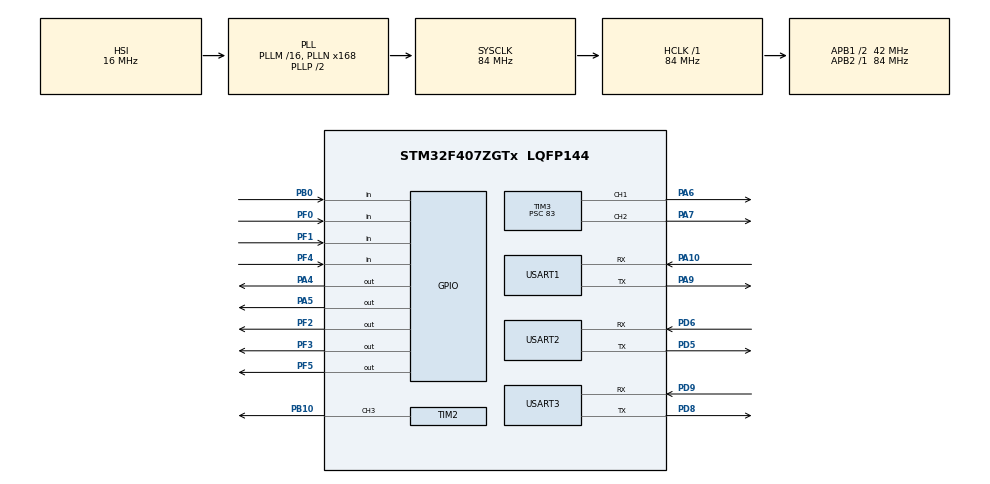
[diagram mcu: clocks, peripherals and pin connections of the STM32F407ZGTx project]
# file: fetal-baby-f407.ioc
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Mcu.Family=STM32F4
Mcu.Name=STM32F407ZGTx
Mcu.Package=LQFP144
NVIC.PriorityGroup=NVIC_PRIORITYGROUP_4
NVIC.USART1_IRQn=true\:6\:0\:false\:false\:true\:true\:true\:true
NVIC.USART2_IRQn=true\:5\:0\:false\:false\:true\:true\:true\:true
NVIC.USART3_IRQn=true\:5\:0\:false\:false\:true\:true\:true\:true
PA4.GPIO_Speed=GPIO_SPEED_FREQ_LOW
PA4.Signal=GPIO_Output
PA5.GPIO_Speed=GPIO_SPEED_FREQ_LOW
PA5.Signal=GPIO_Output
PA6.GPIO_Speed=GPIO_SPEED_FREQ_LOW
PA6.Signal=S_TIM3_CH1
PA7.GPIO_Speed=GPIO_SPEED_FREQ_LOW
PA7.Signal=S_TIM3_CH2
PA9.GPIO_Speed=GPIO_SPEED_FREQ_LOW
PA9.Mode=Asynchronous
PA9.Signal=USART1_TX
PA10.GPIO_Speed=GPIO_SPEED_FREQ_LOW
PA10.Mode=Asynchronous
PA10.Signal=USART1_RX
PA13\ (JTMS-SWDIO).Mode=Serial_Wire
PA13\ (JTMS-SWDIO).Signal=SYS_JTMS-SWDIO
PA14\ (JTCK-SWCLK).Mode=Serial_Wire
PA14\ (JTCK-SWCLK).Signal=SYS_JTCK-SWCLK
PB0.GPIO_PuPd=GPIO_PULLUP
PB0.Signal=GPIO_Input
PB10.GPIO_Speed=GPIO_SPEED_FREQ_LOW
PB10.Signal=S_TIM2_CH3
PD5.GPIO_Speed=GPIO_SPEED_FREQ_LOW
PD5.Mode=Asynchronous
PD5.Signal=USART2_TX
PD6.GPIO_Speed=GPIO_SPEED_FREQ_LOW
PD6.Mode=Asynchronous
PD6.Signal=USART2_RX
PD8.GPIO_Speed=GPIO_SPEED_FREQ_LOW
PD8.Mode=Asynchronous
PD8.Signal=USART3_TX
PD9.GPIO_Speed=GPIO_SPEED_FREQ_LOW
PD9.Mode=Asynchronous
PD9.Signal=USART3_RX
PF0.GPIO_PuPd=GPIO_PULLDOWN
PF0.Signal=GPIO_Input
PF1.GPIO_PuPd=GPIO_PULLDOWN
PF1.Signal=GPIO_Input
PF2.GPIO_Speed=GPIO_SPEED_FREQ_LOW
PF2.Signal=GPIO_Output
PF3.GPIO_Speed=GPIO_SPEED_FREQ_LOW
PF3.Signal=GPIO_Output
PF4.GPIO_PuPd=GPIO_PULLDOWN
PF4.Signal=GPIO_Input
PF5.GPIO_Speed=GPIO_SPEED_FREQ_LOW
PF5.Signal=GPIO_Output
ProjectManager.HeapSize=0x200
ProjectManager.StackSize=0x1000
ProjectManager.TargetToolchain=STM32CubeIDE
RCC.AHBFreq_Value=84000000
RCC.APB1CLKDivider=RCC_HCLK_DIV2
RCC.APB1Freq_Value=42000000
RCC.APB1TimFreq_Value=84000000
RCC.APB2Freq_Value=84000000
RCC.APB2TimFreq_Value=84000000
RCC.CortexFreq_Value=84000000
RCC.HCLKFreq_Value=84000000
RCC.HSE_VALUE=8000000
RCC.PLLM=16
RCC.PLLN=168
RCC.PLLP=RCC_PLLP_DIV2
RCC.PLLQ=7
RCC.PLLSourceVirtual=RCC_PLLSOURCE_HSI
RCC.SYSCLKFreq_VALUE=84000000
RCC.SYSCLKSource=RCC_SYSCLKSOURCE_PLLCLK
RCC.VCOOutputFreq_Value=168000000
SH.S_TIM2_CH3.0=TIM2_CH3,PWM Generation3 CH3
SH.S_TIM3_CH1.0=TIM3_CH1,PWM Generation1 CH1
SH.S_TIM3_CH2.0=TIM3_CH2,PWM Generation2 CH2
TIM2.Channel-PWM\ Generation3\ CH3=TIM_CHANNEL_3
TIM2.Period=99
TIM2.Prescaler=83
TIM3.Channel-PWM\ Generation1\ CH1=TIM_CHANNEL_1
TIM3.Channel-PWM\ Generation2\ CH2=TIM_CHANNEL_2
TIM3.Period=19999
TIM3.Prescaler=83
TIM3.Pulse-PWM\ Generation1\ CH1=1500
TIM3.Pulse-PWM\ Generation2\ CH2=1500
USART1.VirtualMode-Asynchronous=VM_ASYNC
USART2.VirtualMode-Asynchronous=VM_ASYNC
USART3.VirtualMode-Asynchronous=VM_ASYNC
VP_TIM2_VS_ClockSourceINT.Mode=Internal
VP_TIM3_VS_ClockSourceINT.Mode=Internal
board=custom

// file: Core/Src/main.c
/* USER CODE BEGIN Header */
/**
  ******************************************************************************
  * @file           : main.c
  * @brief          : Main program body
  ******************************************************************************
  * @attention
  *
  * Copyright (c) 2026 STMicroelectronics.
  * All rights reserved.
  *
  * This software is licensed under terms that can be found in the LICENSE file
  * in the root directory of this software component.
  * If no LICENSE file comes with this software, it is provided AS-IS.
  *
  ******************************************************************************
  */
/* USER CODE END Header */
#include "main.h"
#include "tim.h"
#include "usart.h"
#include "gpio.h"

/* USER CODE BEGIN Includes */
#include "baby_care_app.h"

/* USER CODE END Includes */

void SystemClock_Config(void);

int main(void)
{

  /* MCU Configuration--------------------------------------------------------*/

  /* Reset of all peripherals, Initializes the Flash interface and the Systick. */
  HAL_Init();

  /* Configure the system clock */
  SystemClock_Config();

  /* Initialize all configured peripherals */
  MX_GPIO_Init();
  MX_TIM2_Init();
  MX_TIM3_Init();
  MX_USART1_UART_Init();
  MX_USART2_UART_Init();
  MX_USART3_UART_Init();
  /* USER CODE BEGIN 2 */
  BabyCare_Init();

  /* USER CODE END 2 */

  /* Infinite loop */
  while (1)
  {

    /* USER CODE BEGIN 3 */
    BabyCare_Task();
  }
  /* USER CODE END 3 */
}

void SystemClock_Config(void)
{
  RCC_OscInitTypeDef RCC_OscInitStruct = {0};
  RCC_ClkInitTypeDef RCC_ClkInitStruct = {0};

  /** Configure the main internal regulator output voltage
  */
  __HAL_RCC_PWR_CLK_ENABLE();
  __HAL_PWR_VOLTAGESCALING_CONFIG(PWR_REGULATOR_VOLTAGE_SCALE1);

  /** Initializes the RCC Oscillators according to the specified parameters
  * in the RCC_OscInitTypeDef structure.
  */
  RCC_OscInitStruct.OscillatorType = RCC_OSCILLATORTYPE_HSI;
  RCC_OscInitStruct.HSIState = RCC_HSI_ON;
  RCC_OscInitStruct.HSICalibrationValue = RCC_HSICALIBRATION_DEFAULT;
  RCC_OscInitStruct.PLL.PLLState = RCC_PLL_ON;
  RCC_OscInitStruct.PLL.PLLSource = RCC_PLLSOURCE_HSI;
  RCC_OscInitStruct.PLL.PLLM = 16;
  RCC_OscInitStruct.PLL.PLLN = 168;
  RCC_OscInitStruct.PLL.PLLP = RCC_PLLP_DIV2;
  RCC_OscInitStruct.PLL.PLLQ = 7;
  if (HAL_RCC_OscConfig(&RCC_OscInitStruct) != HAL_OK)
  {
    Error_Handler();
  }

  /** Initializes the CPU, AHB and APB buses clocks
  */
  RCC_ClkInitStruct.ClockType = RCC_CLOCKTYPE_HCLK|RCC_CLOCKTYPE_SYSCLK
                              |RCC_CLOCKTYPE_PCLK1|RCC_CLOCKTYPE_PCLK2;
  RCC_ClkInitStruct.SYSCLKSource = RCC_SYSCLKSOURCE_PLLCLK;
  RCC_ClkInitStruct.AHBCLKDivider = RCC_SYSCLK_DIV1;
  RCC_ClkInitStruct.APB1CLKDivider = RCC_HCLK_DIV2;
  RCC_ClkInitStruct.APB2CLKDivider = RCC_HCLK_DIV1;

  if (HAL_RCC_ClockConfig(&RCC_ClkInitStruct, FLASH_LATENCY_2) != HAL_OK)
  {
    Error_Handler();
  }
}

/* USER CODE BEGIN 4 */
void HAL_UART_TxCpltCallback(UART_HandleTypeDef *huart)
{
  BabyCare_OnUartTxComplete(huart);
}

void HAL_UART_RxCpltCallback(UART_HandleTypeDef *huart)
{
  BabyCare_OnUartRxComplete(huart);
}

void HAL_UART_ErrorCallback(UART_HandleTypeDef *huart)
{
  BabyCare_OnUartError(huart);
}

/* USER CODE END 4 */

void Error_Handler(void)
{
  __disable_irq();
  while (1)
  {
  }
}
